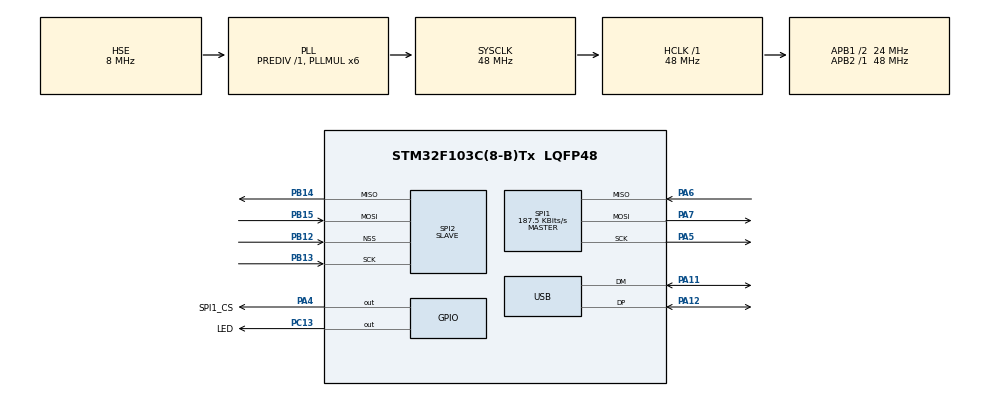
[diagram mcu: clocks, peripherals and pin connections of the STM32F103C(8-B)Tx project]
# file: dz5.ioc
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Mcu.Family=STM32F1
Mcu.Name=STM32F103C(8-B)Tx
Mcu.Package=LQFP48
NVIC.PriorityGroup=NVIC_PRIORITYGROUP_4
NVIC.SPI1_IRQn=true\:0\:0\:false\:false\:true\:true\:true\:true
NVIC.SPI2_IRQn=true\:0\:0\:false\:false\:true\:true\:true\:true
NVIC.USB_LP_CAN1_RX0_IRQn=true\:0\:0\:false\:false\:true\:false\:true\:true
PA11.Mode=Device
PA11.Signal=USB_DM
PA12.Mode=Device
PA12.Signal=USB_DP
PA13.Mode=Serial_Wire
PA13.Signal=SYS_JTMS-SWDIO
PA14.Mode=Serial_Wire
PA14.Signal=SYS_JTCK-SWCLK
PA4.GPIO_Label=SPI1_CS
PA4.GPIO_Speed=GPIO_SPEED_FREQ_MEDIUM
PA4.PinState=GPIO_PIN_SET
PA4.Signal=GPIO_Output
PA5.Mode=Full_Duplex_Master
PA5.Signal=SPI1_SCK
PA6.Mode=Full_Duplex_Master
PA6.Signal=SPI1_MISO
PA7.Mode=Full_Duplex_Master
PA7.Signal=SPI1_MOSI
PB12.Mode=NSS_Signal_Hard_Input
PB12.Signal=SPI2_NSS
PB13.Mode=Full_Duplex_Slave
PB13.Signal=SPI2_SCK
PB14.Mode=Full_Duplex_Slave
PB14.Signal=SPI2_MISO
PB15.Mode=Full_Duplex_Slave
PB15.Signal=SPI2_MOSI
PC13-TAMPER-RTC.GPIO_Label=LED
PC13-TAMPER-RTC.PinState=GPIO_PIN_SET
PC13-TAMPER-RTC.Signal=GPIO_Output
PD0-OSC_IN.Mode=HSE-External-Oscillator
PD0-OSC_IN.Signal=RCC_OSC_IN
PD1-OSC_OUT.Mode=HSE-External-Oscillator
PD1-OSC_OUT.Signal=RCC_OSC_OUT
ProjectManager.HeapSize=0x200
ProjectManager.StackSize=0x400
ProjectManager.TargetToolchain=Makefile
RCC.AHBFreq_Value=48000000
RCC.APB1CLKDivider=RCC_HCLK_DIV2
RCC.APB1Freq_Value=24000000
RCC.APB1TimFreq_Value=48000000
RCC.APB2Freq_Value=48000000
RCC.APB2TimFreq_Value=48000000
RCC.HCLKFreq_Value=48000000
RCC.PLLMUL=RCC_PLL_MUL6
RCC.SYSCLKFreq_VALUE=48000000
RCC.SYSCLKSource=RCC_SYSCLKSOURCE_PLLCLK
RCC.USBFreq_Value=48000000
SPI1.BaudRatePrescaler=SPI_BAUDRATEPRESCALER_256
SPI1.CLKPhase=SPI_PHASE_2EDGE
SPI1.CLKPolarity=SPI_POLARITY_HIGH
SPI1.CalculateBaudRate=187.5 KBits/s
SPI1.Direction=SPI_DIRECTION_2LINES
SPI1.Mode=SPI_MODE_MASTER
SPI1.VirtualType=VM_MASTER
SPI2.CLKPhase=SPI_PHASE_2EDGE
SPI2.CLKPolarity=SPI_POLARITY_HIGH
SPI2.Direction=SPI_DIRECTION_2LINES
SPI2.Mode=SPI_MODE_SLAVE
SPI2.VirtualNSS=VM_NSSHARD
SPI2.VirtualType=VM_SLAVE
USB_DEVICE.CLASS_NAME_FS=CDC
USB_DEVICE.MANUFACTURER_STRING=R6DJO
USB_DEVICE.PRODUCT_STRING_CDC_FS=R6DJO Virtual ComPort
USB_DEVICE.VirtualMode=Cdc
USB_DEVICE.VirtualModeFS=Cdc_FS
VP_USB_DEVICE_VS_USB_DEVICE_CDC_FS.Mode=CDC_FS
board=custom

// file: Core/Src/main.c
/* USER CODE BEGIN Header */
/**
 ******************************************************************************
 * @file           : main.c
 * @brief          : Main program body
 ******************************************************************************
 * @attention
 *
 * Copyright (c) 2023 STMicroelectronics.
 * All rights reserved.
 *
 * This software is licensed under terms that can be found in the LICENSE file
 * in the root directory of this software component.
 * If no LICENSE file comes with this software, it is provided AS-IS.
 *
 ******************************************************************************
 */
/* USER CODE END Header */
#include "main.h"
#include "usb_device.h"

/* USER CODE BEGIN PD */
#define BUFFER_SIZE 32
/* USER CODE END PD */

SPI_HandleTypeDef hspi1;
SPI_HandleTypeDef hspi2;

/* USER CODE BEGIN PV */
uint8_t TX_Data[] = "Hello World!!!";
uint8_t RX_Data[BUFFER_SIZE] = { 0 };
HAL_StatusTypeDef status;
/* USER CODE END PV */

void SystemClock_Config(void);
static void MX_GPIO_Init(void);
static void MX_SPI1_Init(void);
static void MX_SPI2_Init(void);

int main(void)
{

  /* MCU Configuration--------------------------------------------------------*/

  /* Reset of all peripherals, Initializes the Flash interface and the Systick. */
  HAL_Init();

  /* Configure the system clock */
  SystemClock_Config();

  /* Initialize all configured peripherals */
  MX_GPIO_Init();
  MX_USB_DEVICE_Init();
  MX_SPI1_Init();
  MX_SPI2_Init();
  /* USER CODE BEGIN 2 */

   //  uint8_t TX_Data[] = "128\r\n131\r\n134\r\n137\r\n140\r\n143\r\n146\r\n149\r\n152\r\n155\r\n158\r\n162\r\n165\r\n167\r\n170\r\n173\r\n176\r\n179\r\n182\r\n185\r\n188\r\n190\r\n193\r\n196\r\n198\r\n201\r\n203\r\n206\r\n208\r\n211\r\n213\r\n215\r\n218\r\n220\r\n222\r\n224\r\n226\r\n228\r\n230\r\n232\r\n234\r\n235\r\n237\r\n238\r\n240\r\n241\r\n243\r\n244\r\n245\r\n246\r\n248\r\n249\r\n250\r\n250\r\n251\r\n252\r\n253\r\n253\r\n254\r\n254\r\n254\r\n255\r\n255\r\n255\r\n255\r\n255\r\n255\r\n255\r\n254\r\n254\r\n254\r\n253\r\n253\r\n252\r\n251\r\n250\r\n250\r\n249\r\n248\r\n246\r\n245\r\n244\r\n243\r\n241\r\n240\r\n238\r\n237\r\n235\r\n234\r\n232\r\n230\r\n228\r\n226\r\n224\r\n222\r\n220\r\n218\r\n215\r\n213\r\n211\r\n208\r\n206\r\n203\r\n201\r\n198\r\n196\r\n193\r\n190\r\n188\r\n185\r\n182\r\n179\r\n176\r\n173\r\n170\r\n167\r\n165\r\n162\r\n158\r\n155\r\n152\r\n149\r\n146\r\n143\r\n140\r\n137\r\n134\r\n131\r\n128\r\n124\r\n121\r\n118\r\n115\r\n112\r\n109\r\n106\r\n103\r\n100\r\n97\r\n93\r\n90\r\n88\r\n85\r\n82\r\n79\r\n76\r\n73\r\n70\r\n67\r\n65\r\n62\r\n59\r\n57\r\n54\r\n52\r\n49\r\n47\r\n44\r\n42\r\n40\r\n37\r\n35\r\n33\r\n31\r\n29\r\n27\r\n25\r\n23\r\n21\r\n20\r\n18\r\n17\r\n15\r\n14\r\n12\r\n11\r\n10\r\n9\r\n7\r\n6\r\n5\r\n5\r\n4\r\n3\r\n2\r\n2\r\n1\r\n1\r\n1\r\n0\r\n0\r\n0\r\n0\r\n0\r\n0\r\n0\r\n1\r\n1\r\n1\r\n2\r\n2\r\n3\r\n4\r\n5\r\n5\r\n6\r\n7\r\n9\r\n10\r\n11\r\n12\r\n14\r\n15\r\n17\r\n18\r\n20\r\n21\r\n23\r\n25\r\n27\r\n29\r\n31\r\n33\r\n35\r\n37\r\n40\r\n42\r\n44\r\n47\r\n49\r\n52\r\n54\r\n57\r\n59\r\n62\r\n65\r\n67\r\n70\r\n73\r\n76\r\n79\r\n82\r\n85\r\n88\r\n90\r\n93\r\n97\r\n100\r\n103\r\n106\r\n109\r\n112\r\n115\r\n118\r\n121\r\n124\r\n";
   //  uint8_t RX_Data[1652] = { 0 };
   HAL_Delay(1);
   // HAL_GPIO_WritePin(CS_GPIO_Port, CS_Pin, GPIO_PIN_RESET);
   // HAL_Delay(1);
   // HAL_SPI_Receive_IT(&hspi2, RX_Data, sizeof(RX_Data));
   // HAL_Delay(1);
   // HAL_GPIO_WritePin(CS_GPIO_Port, CS_Pin, GPIO_PIN_RESET);
   // HAL_SPI_Transmit(&hspi1, TX_Data, sizeof(TX_Data),5000);
   // HAL_GPIO_WritePin(LED_GPIO_Port, LED_Pin, GPIO_PIN_RESET);
   // HAL_GPIO_WritePin(LED_GPIO_Port, LED_Pin, GPIO_PIN_SET);
   // HAL_GPIO_WritePin(LED_GPIO_Port, LED_Pin, GPIO_PIN_RESET);

   status = HAL_SPI_Receive_IT(&hspi2, RX_Data, sizeof(RX_Data));

   HAL_GPIO_WritePin(SPI1_CS_GPIO_Port,SPI1_CS_Pin,GPIO_PIN_RESET);
   HAL_SPI_Transmit(&hspi1, TX_Data, sizeof(TX_Data),5000);
   HAL_GPIO_WritePin(SPI1_CS_GPIO_Port,SPI1_CS_Pin,GPIO_PIN_SET);

  /* USER CODE END 2 */

  /* Infinite loop */
  /* USER CODE BEGIN WHILE */
   while (1) {
      HAL_Delay(1000);
      HAL_Delay(1);
   }
  /* USER CODE END 3 */
}

void SystemClock_Config(void)
{
  RCC_OscInitTypeDef RCC_OscInitStruct = {0};
  RCC_ClkInitTypeDef RCC_ClkInitStruct = {0};
  RCC_PeriphCLKInitTypeDef PeriphClkInit = {0};

  /** Initializes the RCC Oscillators according to the specified parameters
  * in the RCC_OscInitTypeDef structure.
  */
  RCC_OscInitStruct.OscillatorType = RCC_OSCILLATORTYPE_HSE;
  RCC_OscInitStruct.HSEState = RCC_HSE_ON;
  RCC_OscInitStruct.HSEPredivValue = RCC_HSE_PREDIV_DIV1;
  RCC_OscInitStruct.HSIState = RCC_HSI_ON;
  RCC_OscInitStruct.PLL.PLLState = RCC_PLL_ON;
  RCC_OscInitStruct.PLL.PLLSource = RCC_PLLSOURCE_HSE;
  RCC_OscInitStruct.PLL.PLLMUL = RCC_PLL_MUL6;
  if (HAL_RCC_OscConfig(&RCC_OscInitStruct) != HAL_OK)
  {
    Error_Handler();
  }

  /** Initializes the CPU, AHB and APB buses clocks
  */
  RCC_ClkInitStruct.ClockType = RCC_CLOCKTYPE_HCLK|RCC_CLOCKTYPE_SYSCLK
                              |RCC_CLOCKTYPE_PCLK1|RCC_CLOCKTYPE_PCLK2;
  RCC_ClkInitStruct.SYSCLKSource = RCC_SYSCLKSOURCE_PLLCLK;
  RCC_ClkInitStruct.AHBCLKDivider = RCC_SYSCLK_DIV1;
  RCC_ClkInitStruct.APB1CLKDivider = RCC_HCLK_DIV2;
  RCC_ClkInitStruct.APB2CLKDivider = RCC_HCLK_DIV1;

  if (HAL_RCC_ClockConfig(&RCC_ClkInitStruct, FLASH_LATENCY_1) != HAL_OK)
  {
    Error_Handler();
  }
  PeriphClkInit.PeriphClockSelection = RCC_PERIPHCLK_USB;
  PeriphClkInit.UsbClockSelection = RCC_USBCLKSOURCE_PLL;
  if (HAL_RCCEx_PeriphCLKConfig(&PeriphClkInit) != HAL_OK)
  {
    Error_Handler();
  }
}

static void MX_SPI1_Init(void)
{

  /* SPI1 parameter configuration*/
  hspi1.Instance = SPI1;
  hspi1.Init.Mode = SPI_MODE_MASTER;
  hspi1.Init.Direction = SPI_DIRECTION_2LINES;
  hspi1.Init.DataSize = SPI_DATASIZE_8BIT;
  hspi1.Init.CLKPolarity = SPI_POLARITY_HIGH;
  hspi1.Init.CLKPhase = SPI_PHASE_2EDGE;
  hspi1.Init.NSS = SPI_NSS_SOFT;
  hspi1.Init.BaudRatePrescaler = SPI_BAUDRATEPRESCALER_256;
  hspi1.Init.FirstBit = SPI_FIRSTBIT_MSB;
  hspi1.Init.TIMode = SPI_TIMODE_DISABLE;
  hspi1.Init.CRCCalculation = SPI_CRCCALCULATION_DISABLE;
  hspi1.Init.CRCPolynomial = 10;
  if (HAL_SPI_Init(&hspi1) != HAL_OK)
  {
    Error_Handler();
  }

}

static void MX_SPI2_Init(void)
{

  /* SPI2 parameter configuration*/
  hspi2.Instance = SPI2;
  hspi2.Init.Mode = SPI_MODE_SLAVE;
  hspi2.Init.Direction = SPI_DIRECTION_2LINES;
  hspi2.Init.DataSize = SPI_DATASIZE_8BIT;
  hspi2.Init.CLKPolarity = SPI_POLARITY_HIGH;
  hspi2.Init.CLKPhase = SPI_PHASE_2EDGE;
  hspi2.Init.NSS = SPI_NSS_HARD_INPUT;
  hspi2.Init.FirstBit = SPI_FIRSTBIT_MSB;
  hspi2.Init.TIMode = SPI_TIMODE_DISABLE;
  hspi2.Init.CRCCalculation = SPI_CRCCALCULATION_DISABLE;
  hspi2.Init.CRCPolynomial = 10;
  if (HAL_SPI_Init(&hspi2) != HAL_OK)
  {
    Error_Handler();
  }

}

static void MX_GPIO_Init(void)
{
  GPIO_InitTypeDef GPIO_InitStruct = {0};

  /* GPIO Ports Clock Enable */
  __HAL_RCC_GPIOC_CLK_ENABLE();
  __HAL_RCC_GPIOD_CLK_ENABLE();
  __HAL_RCC_GPIOA_CLK_ENABLE();
  __HAL_RCC_GPIOB_CLK_ENABLE();

  /*Configure GPIO pin Output Level */
  HAL_GPIO_WritePin(LED_GPIO_Port, LED_Pin, GPIO_PIN_SET);

  /*Configure GPIO pin Output Level */
  HAL_GPIO_WritePin(SPI1_CS_GPIO_Port, SPI1_CS_Pin, GPIO_PIN_SET);

  /*Configure GPIO pin : LED_Pin */
  GPIO_InitStruct.Pin = LED_Pin;
  GPIO_InitStruct.Mode = GPIO_MODE_OUTPUT_PP;
  GPIO_InitStruct.Pull = GPIO_NOPULL;
  GPIO_InitStruct.Speed = GPIO_SPEED_FREQ_LOW;
  HAL_GPIO_Init(LED_GPIO_Port, &GPIO_InitStruct);

  /*Configure GPIO pin : SPI1_CS_Pin */
  GPIO_InitStruct.Pin = SPI1_CS_Pin;
  GPIO_InitStruct.Mode = GPIO_MODE_OUTPUT_PP;
  GPIO_InitStruct.Pull = GPIO_NOPULL;
  GPIO_InitStruct.Speed = GPIO_SPEED_FREQ_MEDIUM;
  HAL_GPIO_Init(SPI1_CS_GPIO_Port, &GPIO_InitStruct);

}

/* USER CODE BEGIN 4 */

// void HAL_SPI_TxCpltCallback(SPI_HandleTypeDef* hspi)
// {
//    if (hspi == &hspi1) {
//       HAL_GPIO_WritePin(SPI1_CS_GPIO_Port,SPI1_CS_Pin,GPIO_PIN_SET);
//       HAL_GPIO_TogglePin(LED_GPIO_Port, LED_Pin);
//    }
// }

void HAL_SPI_RxCpltCallback(SPI_HandleTypeDef* hspi)
{
   if (hspi == &hspi2) {
      HAL_GPIO_WritePin(LED_GPIO_Port, LED_Pin, GPIO_PIN_SET);
      HAL_SPI_Receive_IT(&hspi2, RX_Data, BUFFER_SIZE);
   }
}

/* USER CODE END 4 */

void Error_Handler(void)
{
   __disable_irq();
   while (1) {
   }
}
